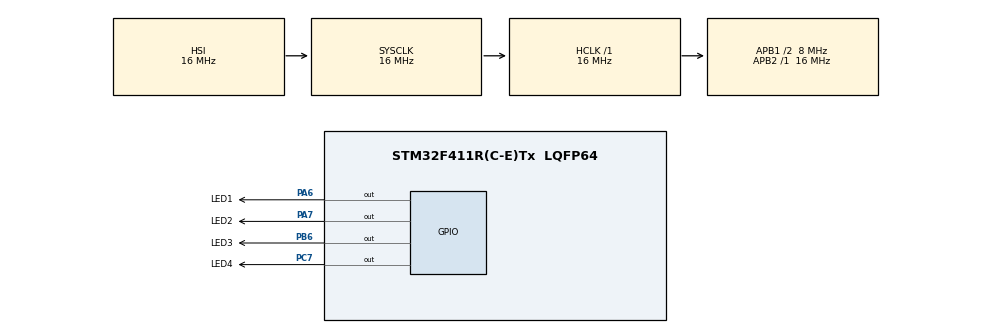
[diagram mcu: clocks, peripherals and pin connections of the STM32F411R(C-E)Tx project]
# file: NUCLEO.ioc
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FREERTOS.Tasks01=defaultTask,0,128,Thread1,Default,NULL,Dynamic,NULL,NULL;myTask02,0,128,runLED,Default,int delay,Dynamic,NULL,NULL
FREERTOS.configUSE_NEWLIB_REENTRANT=0
Mcu.Family=STM32F4
Mcu.Name=STM32F411R(C-E)Tx
Mcu.Package=LQFP64
NVIC.PriorityGroup=NVIC_PRIORITYGROUP_4
PA6.GPIO_Label=LED1
PA6.Signal=GPIO_Output
PA7.GPIO_Label=LED2
PA7.Signal=GPIO_Output
PB6.GPIO_Label=LED3
PB6.Signal=GPIO_Output
PC7.GPIO_Label=LED4
PC7.Signal=GPIO_Output
ProjectManager.HeapSize=0x200
ProjectManager.StackSize=0x400
ProjectManager.TargetToolchain=STM32CubeIDE
RCC.48MHZClocksFreq_Value=84000000
RCC.AHBFreq_Value=16000000
RCC.APB1CLKDivider=RCC_HCLK_DIV2
RCC.APB1Freq_Value=8000000
RCC.APB1TimFreq_Value=16000000
RCC.APB2Freq_Value=16000000
RCC.APB2TimFreq_Value=16000000
RCC.CortexFreq_Value=16000000
RCC.FLatency-AdvancedSettings=FLASH_LATENCY_0
RCC.HCLKFreq_Value=16000000
RCC.HSE_VALUE=8000000
RCC.HSI_VALUE=16000000
RCC.LSE_VALUE=32768
RCC.PLLN=336
RCC.PLLP=RCC_PLLP_DIV4
RCC.SYSCLKFreq_VALUE=16000000
RCC.VCOOutputFreq_Value=336000000
VP_FREERTOS_VS_CMSIS_V1.Mode=CMSIS_V1
board=NUCLEO-F411RE

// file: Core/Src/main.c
/* USER CODE BEGIN Header */
/**
 ******************************************************************************
 * @file           : main.c
 * @brief          : Main program body
 ******************************************************************************
 * @attention
 *
 * Copyright (c) 2023 STMicroelectronics.
 * All rights reserved.
 *
 * This software is licensed under terms that can be found in the LICENSE file
 * in the root directory of this software component.
 * If no LICENSE file comes with this software, it is provided AS-IS.
 *
 ******************************************************************************
 */
/* USER CODE END Header */
#include "main.h"
#include "cmsis_os.h"

/* USER CODE BEGIN Includes */
#include <stdbool.h>
/* USER CODE END Includes */

osThreadId defaultTaskHandle;
osThreadId myTask02Handle;
/* USER CODE BEGIN PV */
int delay;
/* USER CODE END PV */

void SystemClock_Config(void);
static void MX_GPIO_Init(void);
void Thread1(void const * argument);
void runLED(void const * argument);

/* USER CODE BEGIN PFP */
//void runLED(int delay);
/* USER CODE END PFP */

int main(void)
{

  /* MCU Configuration--------------------------------------------------------*/

  /* Reset of all peripherals, Initializes the Flash interface and the Systick. */
  HAL_Init();

  /* Configure the system clock */
  SystemClock_Config();

  /* Initialize all configured peripherals */
  MX_GPIO_Init();

  /* Create the thread(s) */
  /* definition and creation of defaultTask */
  osThreadDef(defaultTask, Thread1, osPriorityNormal, 0, 128);
  defaultTaskHandle = osThreadCreate(osThread(defaultTask), NULL);

  /* definition and creation of myTask02 */
  osThreadDef(myTask02, runLED, osPriorityNormal, 0, 128);
  myTask02Handle = osThreadCreate(osThread(myTask02), (void*) intdelay);

  /* Start scheduler */
  osKernelStart();

  /* We should never get here as control is now taken by the scheduler */
  /* Infinite loop */
	while (1) {

	}
}

void SystemClock_Config(void)
{
  RCC_OscInitTypeDef RCC_OscInitStruct = {0};
  RCC_ClkInitTypeDef RCC_ClkInitStruct = {0};

  /** Configure the main internal regulator output voltage
  */
  __HAL_RCC_PWR_CLK_ENABLE();
  __HAL_PWR_VOLTAGESCALING_CONFIG(PWR_REGULATOR_VOLTAGE_SCALE1);

  /** Initializes the RCC Oscillators according to the specified parameters
  * in the RCC_OscInitTypeDef structure.
  */
  RCC_OscInitStruct.OscillatorType = RCC_OSCILLATORTYPE_HSI;
  RCC_OscInitStruct.HSIState = RCC_HSI_ON;
  RCC_OscInitStruct.HSICalibrationValue = RCC_HSICALIBRATION_DEFAULT;
  RCC_OscInitStruct.PLL.PLLState = RCC_PLL_NONE;
  if (HAL_RCC_OscConfig(&RCC_OscInitStruct) != HAL_OK)
  {
    Error_Handler();
  }

  /** Initializes the CPU, AHB and APB buses clocks
  */
  RCC_ClkInitStruct.ClockType = RCC_CLOCKTYPE_HCLK|RCC_CLOCKTYPE_SYSCLK
                              |RCC_CLOCKTYPE_PCLK1|RCC_CLOCKTYPE_PCLK2;
  RCC_ClkInitStruct.SYSCLKSource = RCC_SYSCLKSOURCE_HSI;
  RCC_ClkInitStruct.AHBCLKDivider = RCC_SYSCLK_DIV1;
  RCC_ClkInitStruct.APB1CLKDivider = RCC_HCLK_DIV2;
  RCC_ClkInitStruct.APB2CLKDivider = RCC_HCLK_DIV1;

  if (HAL_RCC_ClockConfig(&RCC_ClkInitStruct, FLASH_LATENCY_0) != HAL_OK)
  {
    Error_Handler();
  }
}

static void MX_GPIO_Init(void)
{
  GPIO_InitTypeDef GPIO_InitStruct = {0};

  /* GPIO Ports Clock Enable */
  __HAL_RCC_GPIOA_CLK_ENABLE();
  __HAL_RCC_GPIOC_CLK_ENABLE();
  __HAL_RCC_GPIOB_CLK_ENABLE();

  /*Configure GPIO pin Output Level */
  HAL_GPIO_WritePin(GPIOA, LED1_Pin|LED2_Pin, GPIO_PIN_RESET);

  /*Configure GPIO pin Output Level */
  HAL_GPIO_WritePin(LED4_GPIO_Port, LED4_Pin, GPIO_PIN_RESET);

  /*Configure GPIO pin Output Level */
  HAL_GPIO_WritePin(LED3_GPIO_Port, LED3_Pin, GPIO_PIN_RESET);

  /*Configure GPIO pins : LED1_Pin LED2_Pin */
  GPIO_InitStruct.Pin = LED1_Pin|LED2_Pin;
  GPIO_InitStruct.Mode = GPIO_MODE_OUTPUT_PP;
  GPIO_InitStruct.Pull = GPIO_NOPULL;
  GPIO_InitStruct.Speed = GPIO_SPEED_FREQ_LOW;
  HAL_GPIO_Init(GPIOA, &GPIO_InitStruct);

  /*Configure GPIO pin : LED4_Pin */
  GPIO_InitStruct.Pin = LED4_Pin;
  GPIO_InitStruct.Mode = GPIO_MODE_OUTPUT_PP;
  GPIO_InitStruct.Pull = GPIO_NOPULL;
  GPIO_InitStruct.Speed = GPIO_SPEED_FREQ_LOW;
  HAL_GPIO_Init(LED4_GPIO_Port, &GPIO_InitStruct);

  /*Configure GPIO pin : LED3_Pin */
  GPIO_InitStruct.Pin = LED3_Pin;
  GPIO_InitStruct.Mode = GPIO_MODE_OUTPUT_PP;
  GPIO_InitStruct.Pull = GPIO_NOPULL;
  GPIO_InitStruct.Speed = GPIO_SPEED_FREQ_LOW;
  HAL_GPIO_Init(LED3_GPIO_Port, &GPIO_InitStruct);

}

/* USER CODE BEGIN 4 */
//void runLED(int delay) {
//	HAL_GPIO_TogglePin(LED3_GPIO_Port, LED3_Pin);
//	HAL_Delay(delay);
//	HAL_GPIO_TogglePin(LED4_GPIO_Port, LED4_Pin);
//	HAL_Delay(delay);
//}
/* USER CODE END 4 */

void Thread1(void const * argument)
{
  /* USER CODE BEGIN 5 */
	/* Infinite loop */
	for (;;) {
		HAL_GPIO_TogglePin(LED1_GPIO_Port, LED1_Pin);
		HAL_GPIO_TogglePin(LED2_GPIO_Port, LED2_Pin);
		HAL_Delay(200);
		osDelay(1);
	}
  /* USER CODE END 5 */
}

void runLED(void const * argument)
{
  for(;;)
  {
    osDelay(1);
  }
}

void Error_Handler(void)
{
	__disable_irq();
	while (1) {
	}
}
